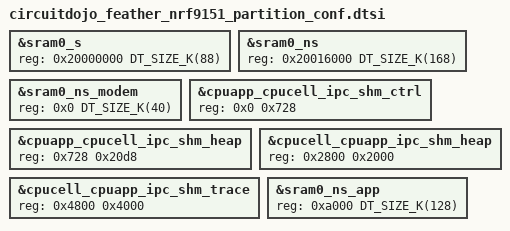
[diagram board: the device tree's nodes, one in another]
/*
 * Copyright (c) 2023 Nordic Semiconductor ASA
 * Copyright (c) 2024-2026 Circuit Dojo LLC
 *
 * SPDX-License-Identifier: Apache-2.0
 */

/*
 * Default SRAM planning when building for nRF91 with
 * ARM TrustZone-M support.
 *
 * - Lowest 88 kB SRAM allocated to Secure image (sram0_s).
 * - 40 kB SRAM reserved for and used by the modem library
 *   (sram0_ns_modem). This memory is Non-Secure.
 * - Upper 128 kB allocated to Non-Secure application (sram0_ns_app).
 */

&sram0_s {
	reg = <0x20000000 DT_SIZE_K(88)>;
};

&sram0_ns {
	reg = <0x20016000 DT_SIZE_K(168)>;
	ranges = <0x0 0x20016000 DT_SIZE_K(168)>;
};

&sram0_ns_modem {
	reg = <0x0 DT_SIZE_K(40)>;
	ranges = <0x0 0x0 DT_SIZE_K(40)>;
};

&cpuapp_cpucell_ipc_shm_ctrl {
	reg = <0x0 0x728>;
};

&cpuapp_cpucell_ipc_shm_heap {
	reg = <0x728 0x20d8>;
};

&cpucell_cpuapp_ipc_shm_heap {
	reg = <0x2800 0x2000>;
};

&cpucell_cpuapp_ipc_shm_trace {
	reg = <0x4800 0x4000>;
};

&sram0_ns_app {
	reg = <0xa000 DT_SIZE_K(128)>;
};
